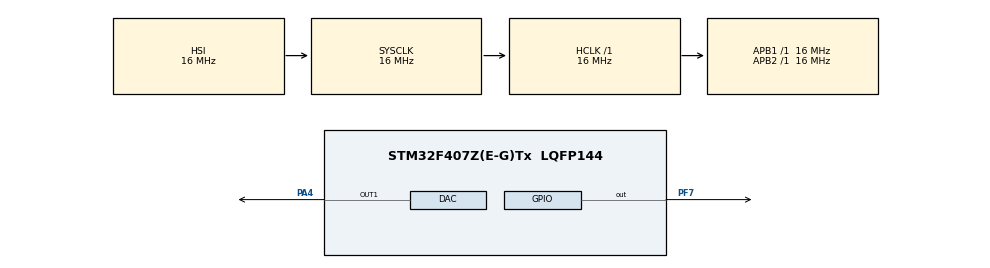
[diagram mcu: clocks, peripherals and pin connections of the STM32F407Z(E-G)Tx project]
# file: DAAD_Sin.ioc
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DAC.DAC_OutputBuffer=DAC_OUTPUTBUFFER_DISABLE
DAC.DAC_Trigger=DAC_TRIGGER_T6_TRGO
Dma.DAC1.0.Direction=DMA_MEMORY_TO_PERIPH
Dma.DAC1.0.FIFOMode=DMA_FIFOMODE_DISABLE
Dma.DAC1.0.Instance=DMA1_Stream5
Dma.DAC1.0.MemDataAlignment=DMA_MDATAALIGN_WORD
Dma.DAC1.0.MemInc=DMA_MINC_ENABLE
Dma.DAC1.0.Mode=DMA_CIRCULAR
Dma.DAC1.0.PeriphDataAlignment=DMA_PDATAALIGN_WORD
Dma.DAC1.0.PeriphInc=DMA_PINC_DISABLE
Dma.DAC1.0.Priority=DMA_PRIORITY_MEDIUM
Dma.Request0=DAC1
Mcu.Family=STM32F4
Mcu.Name=STM32F407Z(E-G)Tx
Mcu.Package=LQFP144
NVIC.DMA1_Stream5_IRQn=true\:0\:0\:false\:false\:true\:false\:true\:true
NVIC.PriorityGroup=NVIC_PRIORITYGROUP_4
NVIC.TIM6_DAC_IRQn=true\:0\:0\:false\:false\:true\:true\:true\:true
PA4.Signal=COMP_DAC1_group
PF7.Signal=GPIO_Output
ProjectManager.HeapSize=0x200
ProjectManager.StackSize=0x400
ProjectManager.TargetToolchain=MDK-ARM V5.32
RCC.AHBFreq_Value=16000000
RCC.APB1Freq_Value=16000000
RCC.APB2Freq_Value=16000000
RCC.CortexFreq_Value=16000000
RCC.HSE_VALUE=25000000
RCC.HSI_VALUE=16000000
RCC.LSE_VALUE=32768
RCC.SYSCLKFreq_VALUE=16000000
RCC.VCOOutputFreq_Value=192000000
SH.COMP_DAC1_group.0=DAC_OUT1,DAC_OUT1
TIM6.Period=1
TIM6.Prescaler=1599
TIM6.TIM_MasterOutputTrigger=TIM_TRGO_UPDATE
VP_TIM6_VS_ClockSourceINT.Mode=Enable_Timer
board=custom

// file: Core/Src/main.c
/* USER CODE BEGIN Header */
/**
  ******************************************************************************
  * @file           : main.c
  * @brief          : Main program body
  ******************************************************************************
  * @attention
  *
  * Copyright (c) 2025 STMicroelectronics.
  * All rights reserved.
  *
  * This software is licensed under terms that can be found in the LICENSE file
  * in the root directory of this software component.
  * If no LICENSE file comes with this software, it is provided AS-IS.
  *
  ******************************************************************************
  */
/* USER CODE END Header */
#include "main.h"
#include "dac.h"
#include "dma.h"
#include "tim.h"
#include "gpio.h"

/* USER CODE BEGIN Includes */
#include "math.h"
/* USER CODE END Includes */

void SystemClock_Config(void);

/* USER CODE BEGIN 0 */
#define SINE_RES 256
#define M_PI 3.14159265358979
uint32_t sine_wave[SINE_RES];
void generate_sine_wave(void)
{
    for (int i = 0; i < SINE_RES; i++) {

        sine_wave[i] = (uint32_t)((sin(i * 2 * M_PI / SINE_RES) + 1) * 2047.5);
    }
}
/* USER CODE END 0 */

int main(void)
{

  /* MCU Configuration--------------------------------------------------------*/

  /* Reset of all peripherals, Initializes the Flash interface and the Systick. */
  HAL_Init();

  /* Configure the system clock */
  SystemClock_Config();

  /* Initialize all configured peripherals */
  MX_GPIO_Init();
  MX_DMA_Init();
  MX_DAC_Init();
  MX_TIM6_Init();
  /* USER CODE BEGIN 2 */
	generate_sine_wave();
	HAL_DAC_Start_DMA(&hdac, DAC_CHANNEL_1, sine_wave, SINE_RES, DAC_ALIGN_12B_R);
	HAL_TIM_Base_Start(&htim6);
  /* USER CODE END 2 */

  /* Infinite loop */
  while (1)
  {

  }
}

void SystemClock_Config(void)
{
  RCC_OscInitTypeDef RCC_OscInitStruct = {0};
  RCC_ClkInitTypeDef RCC_ClkInitStruct = {0};

  /** Configure the main internal regulator output voltage
  */
  __HAL_RCC_PWR_CLK_ENABLE();
  __HAL_PWR_VOLTAGESCALING_CONFIG(PWR_REGULATOR_VOLTAGE_SCALE1);

  /** Initializes the RCC Oscillators according to the specified parameters
  * in the RCC_OscInitTypeDef structure.
  */
  RCC_OscInitStruct.OscillatorType = RCC_OSCILLATORTYPE_HSI;
  RCC_OscInitStruct.HSIState = RCC_HSI_ON;
  RCC_OscInitStruct.HSICalibrationValue = RCC_HSICALIBRATION_DEFAULT;
  RCC_OscInitStruct.PLL.PLLState = RCC_PLL_NONE;
  if (HAL_RCC_OscConfig(&RCC_OscInitStruct) != HAL_OK)
  {
    Error_Handler();
  }

  /** Initializes the CPU, AHB and APB buses clocks
  */
  RCC_ClkInitStruct.ClockType = RCC_CLOCKTYPE_HCLK|RCC_CLOCKTYPE_SYSCLK
                              |RCC_CLOCKTYPE_PCLK1|RCC_CLOCKTYPE_PCLK2;
  RCC_ClkInitStruct.SYSCLKSource = RCC_SYSCLKSOURCE_HSI;
  RCC_ClkInitStruct.AHBCLKDivider = RCC_SYSCLK_DIV1;
  RCC_ClkInitStruct.APB1CLKDivider = RCC_HCLK_DIV1;
  RCC_ClkInitStruct.APB2CLKDivider = RCC_HCLK_DIV1;

  if (HAL_RCC_ClockConfig(&RCC_ClkInitStruct, FLASH_LATENCY_0) != HAL_OK)
  {
    Error_Handler();
  }
}

void Error_Handler(void)
{
  __disable_irq();
  while (1)
  {
  }
}
